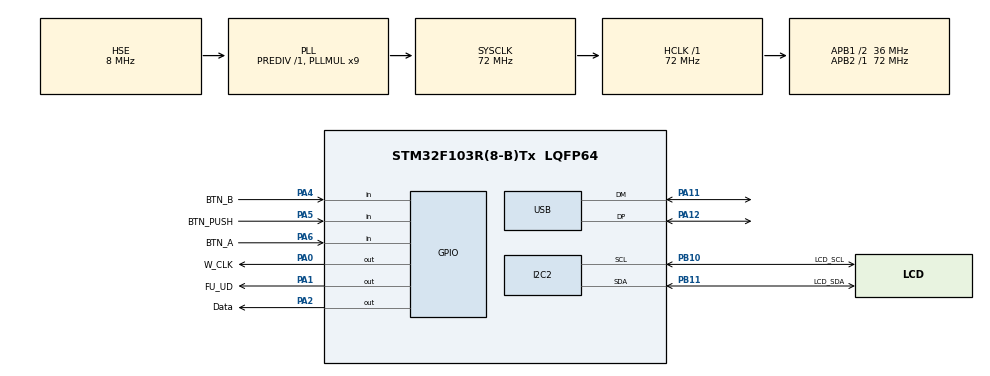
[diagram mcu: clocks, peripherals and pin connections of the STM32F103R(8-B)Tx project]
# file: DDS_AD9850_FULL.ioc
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Mcu.Family=STM32F1
Mcu.Name=STM32F103R(8-B)Tx
Mcu.Package=LQFP64
NVIC.PriorityGroup=NVIC_PRIORITYGROUP_4
NVIC.TIM4_IRQn=true\:15\:0\:false\:false\:true\:false\:false\:true
NVIC.TimeBase=TIM4_IRQn
NVIC.TimeBaseIP=TIM4
NVIC.USB_LP_CAN1_RX0_IRQn=true\:5\:0\:false\:false\:true\:false\:true\:true
PA0-WKUP.GPIO_Label=W_CLK
PA0-WKUP.GPIO_Speed=GPIO_SPEED_FREQ_MEDIUM
PA0-WKUP.Signal=GPIO_Output
PA1.GPIO_Label=FU_UD
PA1.GPIO_Speed=GPIO_SPEED_FREQ_MEDIUM
PA1.Signal=GPIO_Output
PA11.Mode=Device
PA11.Signal=USB_DM
PA12.Mode=Device
PA12.Signal=USB_DP
PA13.Mode=Serial_Wire
PA13.Signal=SYS_JTMS-SWDIO
PA14.Mode=Serial_Wire
PA14.Signal=SYS_JTCK-SWCLK
PA2.GPIO_Label=Data
PA2.GPIO_Speed=GPIO_SPEED_FREQ_MEDIUM
PA2.Signal=GPIO_Output
PA4.GPIO_Label=BTN_B
PA4.GPIO_PuPd=GPIO_PULLDOWN
PA4.Signal=GPIO_Input
PA5.GPIO_Label=BTN_PUSH
PA5.GPIO_PuPd=GPIO_PULLUP
PA5.Signal=GPIO_Input
PA6.GPIO_Label=BTN_A
PA6.Signal=GPIO_Input
PB10.GPIO_Label=LCD_SCL
PB10.GPIO_Pu=GPIO_PULLUP
PB10.Mode=I2C
PB10.Signal=I2C2_SCL
PB11.GPIO_Label=LCD_SDA
PB11.GPIO_Pu=GPIO_PULLUP
PB11.Mode=I2C
PB11.Signal=I2C2_SDA
PC14-OSC32_IN.Mode=LSE-External-Oscillator
PC14-OSC32_IN.Signal=RCC_OSC32_IN
PC15-OSC32_OUT.Mode=LSE-External-Oscillator
PC15-OSC32_OUT.Signal=RCC_OSC32_OUT
PD0-OSC_IN.Mode=HSE-External-Oscillator
PD0-OSC_IN.Signal=RCC_OSC_IN
PD1-OSC_OUT.Mode=HSE-External-Oscillator
PD1-OSC_OUT.Signal=RCC_OSC_OUT
ProjectManager.HeapSize=0x200
ProjectManager.StackSize=0x400
ProjectManager.TargetToolchain=STM32CubeIDE
RCC.ADCPresc=RCC_ADCPCLK2_DIV6
RCC.AHBFreq_Value=72000000
RCC.APB1CLKDivider=RCC_HCLK_DIV2
RCC.APB1Freq_Value=36000000
RCC.APB1TimFreq_Value=72000000
RCC.APB2Freq_Value=72000000
RCC.APB2TimFreq_Value=72000000
RCC.EnbaleCSS=true
RCC.HCLKFreq_Value=72000000
RCC.HSEDivPLL=RCC_HSE_PREDIV_DIV1
RCC.PLLMUL=RCC_PLL_MUL9
RCC.PLLSourceVirtual=RCC_PLLSOURCE_HSE
RCC.SYSCLKFreq_VALUE=72000000
RCC.SYSCLKSource=RCC_SYSCLKSOURCE_PLLCLK
RCC.USBFreq_Value=48000000
RCC.USBPrescaler=RCC_USBCLKSOURCE_PLL_DIV1_5
USB_DEVICE.CLASS_NAME_FS=CDC
USB_DEVICE.VirtualMode-CDC_FS=Cdc
USB_DEVICE.VirtualModeFS=Cdc_FS
VP_SYS_VS_tim4.Mode=TIM4
VP_USB_DEVICE_VS_USB_DEVICE_CDC_FS.Mode=CDC_FS
board=custom

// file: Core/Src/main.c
/* USER CODE BEGIN Header */
/**
  ******************************************************************************
  * @file           : main.c
  * @brief          : Main program body
  ******************************************************************************
  * @attention
  *
  * <h2><center>&copy; Copyright (c) 2020 STMicroelectronics.
  * All rights reserved.</center></h2>
  *
  * This software component is licensed by ST under BSD 3-Clause license,
  * the "License"; You may not use this file except in compliance with the
  * License. You may obtain a copy of the License at:
  *                        opensource.org/licenses/BSD-3-Clause
  *
  ******************************************************************************
  */
/* USER CODE END Header */

#include "main.h"
#include "usb_device.h"

/* USER CODE BEGIN Includes */
#include "App.h"
/* USER CODE END Includes */

I2C_HandleTypeDef hi2c2;

void SystemClock_Config(void);
static void MX_GPIO_Init(void);
static void MX_I2C2_Init(void);

int main(void)
{

  /* MCU Configuration--------------------------------------------------------*/

  /* Reset of all peripherals, Initializes the Flash interface and the Systick. */
  HAL_Init();

  /* Configure the system clock */
  SystemClock_Config();

  /* USER CODE BEGIN SysInit */
  /* The Blue Pill has no USB D+ pull-up switch. Pull D+ (PA12) low for a moment so the
   * PC sees a disconnect and enumerates the device again after a reset / reflash. */
  {
    GPIO_InitTypeDef g = {0};
    __HAL_RCC_GPIOA_CLK_ENABLE();
    HAL_GPIO_WritePin(GPIOA, GPIO_PIN_12, GPIO_PIN_RESET);
    g.Pin = GPIO_PIN_12;
    g.Mode = GPIO_MODE_OUTPUT_PP;
    g.Speed = GPIO_SPEED_FREQ_LOW;
    HAL_GPIO_Init(GPIOA, &g);
    HAL_Delay(20);
    HAL_GPIO_DeInit(GPIOA, GPIO_PIN_12);
  }
  /* USER CODE END SysInit */

  /* Initialize all configured peripherals */
  MX_GPIO_Init();
  MX_I2C2_Init();
  MX_USB_DEVICE_Init();
  /* USER CODE BEGIN 2 */
  App_Start();   /* creates the tasks and starts FreeRTOS; does not return */
  /* USER CODE END 2 */

  /* Infinite loop */
  while (1)
  {

  }
}

void SystemClock_Config(void)
{
  RCC_OscInitTypeDef RCC_OscInitStruct = {0};
  RCC_ClkInitTypeDef RCC_ClkInitStruct = {0};
  RCC_PeriphCLKInitTypeDef PeriphClkInit = {0};

  /** Initializes the CPU, AHB and APB busses clocks
  */
  RCC_OscInitStruct.OscillatorType = RCC_OSCILLATORTYPE_HSE;
  RCC_OscInitStruct.HSEState = RCC_HSE_ON;
  RCC_OscInitStruct.HSEPredivValue = RCC_HSE_PREDIV_DIV1;
  RCC_OscInitStruct.HSIState = RCC_HSI_ON;
  RCC_OscInitStruct.PLL.PLLState = RCC_PLL_ON;
  RCC_OscInitStruct.PLL.PLLSource = RCC_PLLSOURCE_HSE;
  RCC_OscInitStruct.PLL.PLLMUL = RCC_PLL_MUL9;
  if (HAL_RCC_OscConfig(&RCC_OscInitStruct) != HAL_OK)
  {
    Error_Handler();
  }
  /** Initializes the CPU, AHB and APB busses clocks
  */
  RCC_ClkInitStruct.ClockType = RCC_CLOCKTYPE_HCLK|RCC_CLOCKTYPE_SYSCLK
                              |RCC_CLOCKTYPE_PCLK1|RCC_CLOCKTYPE_PCLK2;
  RCC_ClkInitStruct.SYSCLKSource = RCC_SYSCLKSOURCE_PLLCLK;
  RCC_ClkInitStruct.AHBCLKDivider = RCC_SYSCLK_DIV1;
  RCC_ClkInitStruct.APB1CLKDivider = RCC_HCLK_DIV2;
  RCC_ClkInitStruct.APB2CLKDivider = RCC_HCLK_DIV1;

  if (HAL_RCC_ClockConfig(&RCC_ClkInitStruct, FLASH_LATENCY_2) != HAL_OK)
  {
    Error_Handler();
  }
  PeriphClkInit.PeriphClockSelection = RCC_PERIPHCLK_USB;
  PeriphClkInit.UsbClockSelection = RCC_USBCLKSOURCE_PLL_DIV1_5;
  if (HAL_RCCEx_PeriphCLKConfig(&PeriphClkInit) != HAL_OK)
  {
    Error_Handler();
  }
  /** Enables the Clock Security System
  */
  HAL_RCC_EnableCSS();
}

static void MX_I2C2_Init(void)
{

  hi2c2.Instance = I2C2;
  hi2c2.Init.ClockSpeed = 100000;
  hi2c2.Init.DutyCycle = I2C_DUTYCYCLE_2;
  hi2c2.Init.OwnAddress1 = 0;
  hi2c2.Init.AddressingMode = I2C_ADDRESSINGMODE_7BIT;
  hi2c2.Init.DualAddressMode = I2C_DUALADDRESS_DISABLE;
  hi2c2.Init.OwnAddress2 = 0;
  hi2c2.Init.GeneralCallMode = I2C_GENERALCALL_DISABLE;
  hi2c2.Init.NoStretchMode = I2C_NOSTRETCH_DISABLE;
  if (HAL_I2C_Init(&hi2c2) != HAL_OK)
  {
    Error_Handler();
  }

}

static void MX_GPIO_Init(void)
{
  GPIO_InitTypeDef GPIO_InitStruct = {0};

  /* GPIO Ports Clock Enable */
  __HAL_RCC_GPIOC_CLK_ENABLE();
  __HAL_RCC_GPIOD_CLK_ENABLE();
  __HAL_RCC_GPIOA_CLK_ENABLE();
  __HAL_RCC_GPIOB_CLK_ENABLE();

  /*Configure GPIO pin Output Level */
  HAL_GPIO_WritePin(GPIOA, W_CLK_Pin|FU_UD_Pin|Data_Pin, GPIO_PIN_RESET);

  /*Configure GPIO pins : W_CLK_Pin FU_UD_Pin Data_Pin */
  GPIO_InitStruct.Pin = W_CLK_Pin|FU_UD_Pin|Data_Pin;
  GPIO_InitStruct.Mode = GPIO_MODE_OUTPUT_PP;
  GPIO_InitStruct.Pull = GPIO_NOPULL;
  GPIO_InitStruct.Speed = GPIO_SPEED_FREQ_MEDIUM;
  HAL_GPIO_Init(GPIOA, &GPIO_InitStruct);

  /*Configure GPIO pin : BTN_B_Pin */
  GPIO_InitStruct.Pin = BTN_B_Pin;
  GPIO_InitStruct.Mode = GPIO_MODE_INPUT;
  GPIO_InitStruct.Pull = GPIO_PULLDOWN;
  HAL_GPIO_Init(GPIOA, &GPIO_InitStruct);

  /*Configure GPIO pin : BTN_PUSH_Pin */
  GPIO_InitStruct.Pin = BTN_PUSH_Pin;
  GPIO_InitStruct.Mode = GPIO_MODE_INPUT;
  GPIO_InitStruct.Pull = GPIO_PULLUP;
  HAL_GPIO_Init(BTN_PUSH_GPIO_Port, &GPIO_InitStruct);

  /*Configure GPIO pin : BTN_A_Pin */
  GPIO_InitStruct.Pin = BTN_A_Pin;
  GPIO_InitStruct.Mode = GPIO_MODE_INPUT;
  GPIO_InitStruct.Pull = GPIO_NOPULL;
  HAL_GPIO_Init(BTN_A_GPIO_Port, &GPIO_InitStruct);

}

void HAL_TIM_PeriodElapsedCallback(TIM_HandleTypeDef *htim)
{
  if (htim->Instance == TIM4)
  {
    HAL_IncTick();
  }
}

void Error_Handler(void)
{
}

/************************ (C) COPYRIGHT STMicroelectronics *****END OF FILE****/
